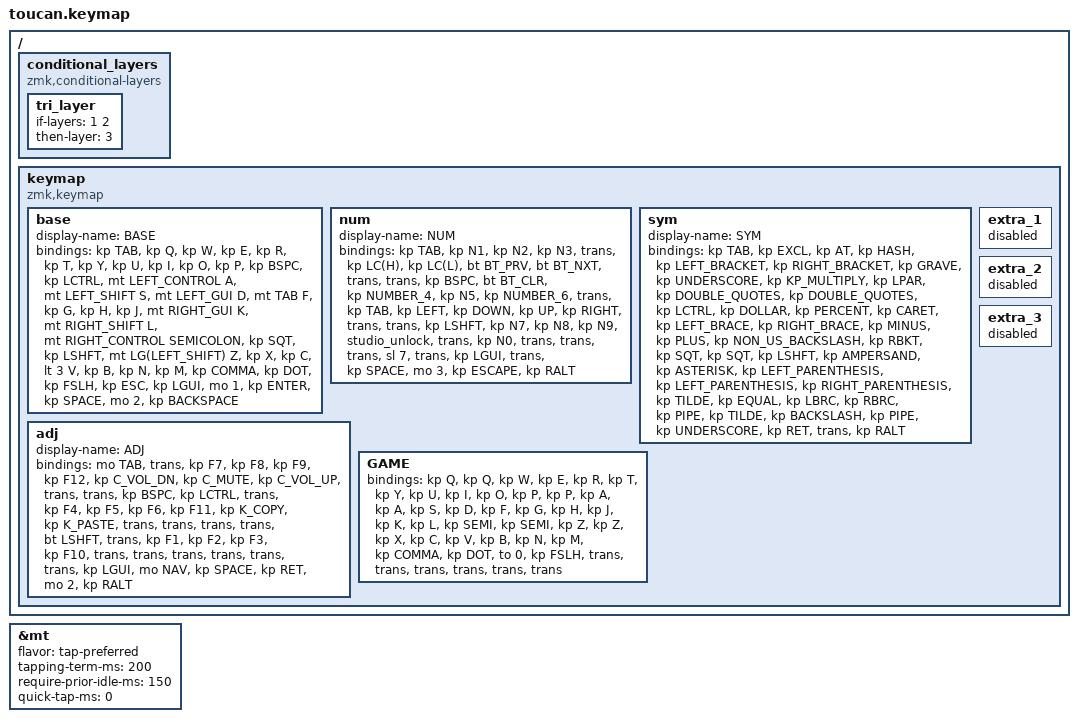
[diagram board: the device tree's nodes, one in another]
#include <behaviors.dtsi>
#include <dt-bindings/zmk/bt.h>
#include <dt-bindings/zmk/keys.h>

#define BASE 0
#define NAV  1
#define SYM  2
#define ADJ  3

&mt {
    flavor = "tap-preferred";
    tapping-term-ms = <200>;
    require-prior-idle-ms = <150>;
    quick-tap-ms = <0>;
};

/ {
    conditional_layers {
        compatible = "zmk,conditional-layers";

        tri_layer {
            if-layers = <1 2>;
            then-layer = <3>;
        };
    };

    keymap {
        compatible = "zmk,keymap";

        base {
            display-name = "BASE";
            bindings = <
&kp TAB  &kp Q  &kp W  &kp E  &kp R  &kp T  &kp Y  &kp U  &kp I  &kp O  &kp P  &kp BSPC  &kp LCTRL  &mt LEFT_CONTROL A  &mt LEFT_SHIFT S  &mt LEFT_GUI D  &mt TAB F  &kp G  &kp H  &kp J  &mt RIGHT_GUI K  &mt RIGHT_SHIFT L  &mt RIGHT_CONTROL SEMICOLON  &kp SQT  &kp LSHFT  &mt LG(LEFT_SHIFT) Z  &kp X  &kp C  &lt 3 V  &kp B  &kp N  &kp M  &kp COMMA  &kp DOT  &kp FSLH  &kp ESC  &kp LGUI  &mo 1  &kp ENTER  &kp SPACE  &mo 2  &kp BACKSPACE
            >;
        };

        num {
            display-name = "NUM";
            bindings = <
&kp TAB  &kp N1  &kp N2  &kp N3  &trans  &kp LC(H)  &kp LC(L)  &bt BT_PRV  &bt BT_NXT  &trans  &trans  &kp BSPC  &bt BT_CLR  &kp NUMBER_4  &kp N5  &kp NUMBER_6  &trans  &kp TAB  &kp LEFT  &kp DOWN  &kp UP  &kp RIGHT  &trans  &trans  &kp LSHFT  &kp N7  &kp N8  &kp N9  &studio_unlock  &trans  &kp N0  &trans  &trans  &trans  &sl 7  &trans  &kp LGUI  &trans  &kp SPACE  &mo 3  &kp ESCAPE  &kp RALT
            >;
        };

        sym {
            display-name = "SYM";
            bindings = <
&kp TAB  &kp EXCL  &kp AT  &kp HASH  &kp LEFT_BRACKET  &kp RIGHT_BRACKET  &kp GRAVE  &kp UNDERSCORE  &kp KP_MULTIPLY  &kp LPAR  &kp DOUBLE_QUOTES  &kp DOUBLE_QUOTES  &kp LCTRL  &kp DOLLAR  &kp PERCENT  &kp CARET  &kp LEFT_BRACE  &kp RIGHT_BRACE  &kp MINUS  &kp PLUS  &kp NON_US_BACKSLASH  &kp RBKT  &kp SQT  &kp SQT  &kp LSHFT  &kp AMPERSAND  &kp ASTERISK  &kp LEFT_PARENTHESIS  &kp LEFT_PARENTHESIS  &kp RIGHT_PARENTHESIS  &kp TILDE  &kp EQUAL  &kp LBRC  &kp RBRC  &kp PIPE  &kp TILDE  &kp BACKSLASH  &kp PIPE  &kp UNDERSCORE  &kp RET  &trans  &kp RALT
            >;
        };

        adj {
            display-name = "ADJ";
            bindings = <
&mo TAB  &trans  &kp F7  &kp F8  &kp F9  &kp F12  &kp C_VOL_DN  &kp C_MUTE  &kp C_VOL_UP  &trans  &trans  &kp BSPC  &kp LCTRL  &trans  &kp F4  &kp F5  &kp F6  &kp F11  &kp K_COPY  &kp K_PASTE  &trans  &trans  &trans  &trans  &bt LSHFT  &trans  &kp F1  &kp F2  &kp F3  &kp F10  &trans  &trans  &trans  &trans  &trans  &trans  &kp LGUI  &mo NAV  &kp SPACE  &kp RET  &mo 2  &kp RALT
            >;
        };

        extra_1 { status = "reserved"; };

        extra_2 { status = "reserved"; };

        extra_3 { status = "reserved"; };

        GAME {
            bindings = <
&kp Q  &kp Q  &kp W  &kp E  &kp R  &kp T  &kp Y  &kp U  &kp I  &kp O  &kp P  &kp P  &kp A  &kp A  &kp S  &kp D  &kp F  &kp G  &kp H  &kp J  &kp K  &kp L  &kp SEMI  &kp SEMI  &kp Z  &kp Z  &kp X  &kp C  &kp V  &kp B  &kp N  &kp M  &kp COMMA  &kp DOT  &to 0  &kp FSLH  &trans  &trans  &trans  &trans  &trans  &trans
            >;
        };
    };
};
